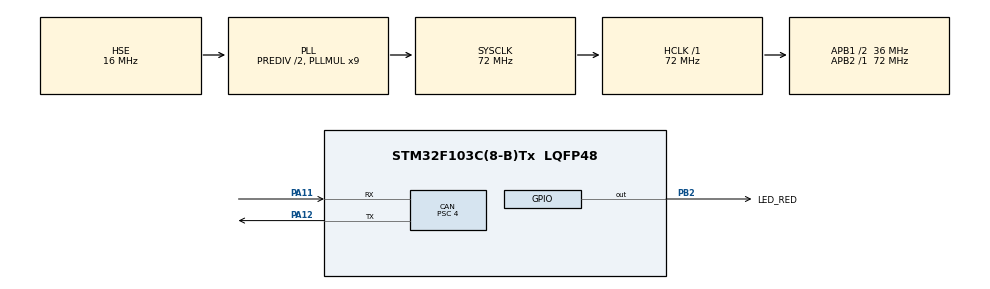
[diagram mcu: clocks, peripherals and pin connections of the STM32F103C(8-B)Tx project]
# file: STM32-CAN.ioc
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CAN.BS1=CAN_BS1_15TQ
CAN.BS2=CAN_BS2_2TQ
CAN.CalculateBaudRate=500000
CAN.CalculateTimeBit=2000
CAN.CalculateTimeQuantum=111.11111111111111
CAN.NART=ENABLE
CAN.Prescaler=4
CAN.SJW=CAN_SJW_2TQ
Mcu.Family=STM32F1
Mcu.Name=STM32F103C(8-B)Tx
Mcu.Package=LQFP48
NVIC.PriorityGroup=NVIC_PRIORITYGROUP_4
NVIC.USB_LP_CAN1_RX0_IRQn=true\:0\:0\:false\:false\:true\:true\:true\:true
PA11.Mode=CAN_Activate
PA11.Signal=CAN_RX
PA12.Mode=CAN_Activate
PA12.Signal=CAN_TX
PA13.GPIO_Label=J7_SWDIO
PA13.Mode=Serial_Wire
PA13.Signal=SYS_JTMS-SWDIO
PA14.GPIO_Label=J7_SWCLK
PA14.Mode=Serial_Wire
PA14.Signal=SYS_JTCK-SWCLK
PB2.GPIO_Label=LED_RED
PB2.Signal=GPIO_Output
PD0-OSC_IN.Mode=HSE-External-Oscillator
PD0-OSC_IN.Signal=RCC_OSC_IN
PD1-OSC_OUT.Mode=HSE-External-Oscillator
PD1-OSC_OUT.Signal=RCC_OSC_OUT
ProjectManager.HeapSize=0x200
ProjectManager.StackSize=0x400
ProjectManager.TargetToolchain=STM32CubeIDE
RCC.AHBFreq_Value=72000000
RCC.APB1CLKDivider=RCC_HCLK_DIV2
RCC.APB1Freq_Value=36000000
RCC.APB1TimFreq_Value=72000000
RCC.APB2Freq_Value=72000000
RCC.APB2TimFreq_Value=72000000
RCC.HCLKFreq_Value=72000000
RCC.HSEDivPLL=RCC_HSE_PREDIV_DIV2
RCC.HSE_VALUE=16000000
RCC.PLLMUL=RCC_PLL_MUL9
RCC.PLLSourceVirtual=RCC_PLLSOURCE_HSE
RCC.SYSCLKFreq_VALUE=72000000
RCC.SYSCLKSource=RCC_SYSCLKSOURCE_PLLCLK
RCC.USBFreq_Value=72000000
board=custom

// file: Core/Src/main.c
/* USER CODE BEGIN Header */
/**
 ******************************************************************************
 * @file           : main.c
 * @brief          : Main program body
 ******************************************************************************
 * @attention
 *
 * Copyright (c) 2024 STMicroelectronics.
 * All rights reserved.
 *
 * This software is licensed under terms that can be found in the LICENSE file
 * in the root directory of this software component.
 * If no LICENSE file comes with this software, it is provided AS-IS.
 *
 ******************************************************************************
 */
/* USER CODE END Header */
#include "main.h"

CAN_HandleTypeDef hcan;

/* USER CODE BEGIN PV */
// CAN Tx
CAN_TxHeaderTypeDef TxHeader;
uint8_t TxData[8];
uint32_t TxMailbox;

// CAN Rx
CAN_FilterTypeDef canfilterconfig;
CAN_RxHeaderTypeDef RxHeader;
uint8_t RxData[8];

/* USER CODE END PV */

void SystemClock_Config(void);
static void MX_GPIO_Init(void);
static void MX_CAN_Init(void);

/* USER CODE BEGIN 0 */

void setupTxCAN()
{
    TxHeader.StdId = 0x321;
    TxHeader.ExtId = 0x01;
    TxHeader.RTR = CAN_RTR_DATA;
    TxHeader.IDE = CAN_ID_EXT;
    TxHeader.DLC = 8;
    TxHeader.TransmitGlobalTime = DISABLE;

    TxData[0] = 0xA0;
    TxData[1] = 0xA1;
    TxData[2] = 0xA2;
    TxData[3] = 0xA3;
    TxData[4] = 0xA4;
    TxData[5] = 0xA5;
    TxData[6] = 0xA6;
    TxData[7] = 0xA7;
}

void setupRxCAN()
{
    canfilterconfig.FilterBank = 0;
    canfilterconfig.FilterMode = CAN_FILTERMODE_IDMASK;
    canfilterconfig.FilterScale = CAN_FILTERSCALE_32BIT;
    canfilterconfig.FilterIdHigh = 0x0000;
    canfilterconfig.FilterIdLow = 0x0356 << 3;  //read only 959. nothing else
    canfilterconfig.FilterMaskIdHigh = 0x0000;
    canfilterconfig.FilterMaskIdLow = 0xFFF8;
    canfilterconfig.FilterFIFOAssignment = CAN_RX_FIFO0;
    canfilterconfig.FilterActivation = ENABLE;
    canfilterconfig.SlaveStartFilterBank = 14;

    HAL_CAN_ConfigFilter(&hcan, &canfilterconfig);
    HAL_CAN_ActivateNotification(&hcan, CAN_IT_RX_FIFO0_MSG_PENDING); //enable interrupts
}

void txCAN()
{
    HAL_StatusTypeDef can_result = HAL_CAN_AddTxMessage(&hcan, &TxHeader,
            TxData, &TxMailbox);
    if (can_result != HAL_OK)
    {
        Error_Handler();
    }
}

/**
 * @brief  Rx Fifo 0 message pending callback in non blocking mode
 * @param  CanHandle: pointer to a CAN_HandleTypeDef structure that contains
 *         the configuration information for the specified CAN.
 * @retval None
 */
void HAL_CAN_RxFifo0MsgPendingCallback(CAN_HandleTypeDef *CanHandle)
{
    /* Get RX message */
    if (HAL_CAN_GetRxMessage(CanHandle, CAN_RX_FIFO0, &RxHeader, RxData)
            != HAL_OK)
    {
        /* Reception Error */
        Error_Handler();
    }

    HAL_GPIO_TogglePin(GPIOB, GPIO_PIN_2);
    // Echo received CAN message

    //RxData[7] = RxData[7] + 1;
    HAL_CAN_AddTxMessage(&hcan, &TxHeader, RxData, &TxMailbox);
}

uint32_t getUs(void)
{

    uint32_t usTicks = HAL_RCC_GetSysClockFreq() / 1000000;

    register uint32_t ms, cycle_cnt;
    do
    {
        ms = HAL_GetTick();
        cycle_cnt = SysTick->VAL;
    } while (ms != HAL_GetTick());
    return (ms * 1000) + (usTicks * 1000 - cycle_cnt) / usTicks;
}

void delayUs(uint16_t micros)
{
    uint32_t start = getUs();
    while (getUs() - start < (uint32_t) micros)
    {
        asm("nop");
    }
}

/* USER CODE END 0 */

int main(void)
{

  /* MCU Configuration--------------------------------------------------------*/

  /* Reset of all peripherals, Initializes the Flash interface and the Systick. */
  HAL_Init();

  /* Configure the system clock */
  SystemClock_Config();

  /* Initialize all configured peripherals */
  MX_GPIO_Init();
  MX_CAN_Init();
  /* USER CODE BEGIN 2 */
    setupTxCAN();
    setupRxCAN();
  /* USER CODE END 2 */

  /* Infinite loop */
  /* USER CODE BEGIN WHILE */
    while (1)
    {
        txCAN();
//        HAL_GPIO_TogglePin(GPIOB, GPIO_PIN_2);
        //delayUs(5000000);
        HAL_Delay(500);
    /* USER CODE END WHILE */

    }
}

void SystemClock_Config(void)
{
  RCC_OscInitTypeDef RCC_OscInitStruct = {0};
  RCC_ClkInitTypeDef RCC_ClkInitStruct = {0};

  /** Initializes the RCC Oscillators according to the specified parameters
  * in the RCC_OscInitTypeDef structure.
  */
  RCC_OscInitStruct.OscillatorType = RCC_OSCILLATORTYPE_HSE;
  RCC_OscInitStruct.HSEState = RCC_HSE_ON;
  RCC_OscInitStruct.HSEPredivValue = RCC_HSE_PREDIV_DIV2;
  RCC_OscInitStruct.HSIState = RCC_HSI_ON;
  RCC_OscInitStruct.PLL.PLLState = RCC_PLL_ON;
  RCC_OscInitStruct.PLL.PLLSource = RCC_PLLSOURCE_HSE;
  RCC_OscInitStruct.PLL.PLLMUL = RCC_PLL_MUL9;
  if (HAL_RCC_OscConfig(&RCC_OscInitStruct) != HAL_OK)
  {
    Error_Handler();
  }

  /** Initializes the CPU, AHB and APB buses clocks
  */
  RCC_ClkInitStruct.ClockType = RCC_CLOCKTYPE_HCLK|RCC_CLOCKTYPE_SYSCLK
                              |RCC_CLOCKTYPE_PCLK1|RCC_CLOCKTYPE_PCLK2;
  RCC_ClkInitStruct.SYSCLKSource = RCC_SYSCLKSOURCE_PLLCLK;
  RCC_ClkInitStruct.AHBCLKDivider = RCC_SYSCLK_DIV1;
  RCC_ClkInitStruct.APB1CLKDivider = RCC_HCLK_DIV2;
  RCC_ClkInitStruct.APB2CLKDivider = RCC_HCLK_DIV1;

  if (HAL_RCC_ClockConfig(&RCC_ClkInitStruct, FLASH_LATENCY_2) != HAL_OK)
  {
    Error_Handler();
  }
}

static void MX_CAN_Init(void)
{

  hcan.Instance = CAN1;
  hcan.Init.Prescaler = 4;
  hcan.Init.Mode = CAN_MODE_NORMAL;
  hcan.Init.SyncJumpWidth = CAN_SJW_2TQ;
  hcan.Init.TimeSeg1 = CAN_BS1_15TQ;
  hcan.Init.TimeSeg2 = CAN_BS2_2TQ;
  hcan.Init.TimeTriggeredMode = DISABLE;
  hcan.Init.AutoBusOff = DISABLE;
  hcan.Init.AutoWakeUp = DISABLE;
  hcan.Init.AutoRetransmission = ENABLE;
  hcan.Init.ReceiveFifoLocked = DISABLE;
  hcan.Init.TransmitFifoPriority = DISABLE;
  if (HAL_CAN_Init(&hcan) != HAL_OK)
  {
    Error_Handler();
  }
  /* USER CODE BEGIN CAN_Init 2 */

    if (HAL_CAN_Start(&hcan) != HAL_OK)
    {
        /* Start Error */
        Error_Handler();
    }

  /* USER CODE END CAN_Init 2 */

}

static void MX_GPIO_Init(void)
{
  GPIO_InitTypeDef GPIO_InitStruct = {0};

  /* GPIO Ports Clock Enable */
  __HAL_RCC_GPIOD_CLK_ENABLE();
  __HAL_RCC_GPIOB_CLK_ENABLE();
  __HAL_RCC_GPIOA_CLK_ENABLE();

  /*Configure GPIO pin Output Level */
  HAL_GPIO_WritePin(LED_RED_GPIO_Port, LED_RED_Pin, GPIO_PIN_RESET);

  /*Configure GPIO pin : LED_RED_Pin */
  GPIO_InitStruct.Pin = LED_RED_Pin;
  GPIO_InitStruct.Mode = GPIO_MODE_OUTPUT_PP;
  GPIO_InitStruct.Pull = GPIO_NOPULL;
  GPIO_InitStruct.Speed = GPIO_SPEED_FREQ_LOW;
  HAL_GPIO_Init(LED_RED_GPIO_Port, &GPIO_InitStruct);

}

void Error_Handler(void)
{
  /* USER CODE BEGIN Error_Handler_Debug */
    /* User can add his own implementation to report the HAL error return state */
    __disable_irq();
    uint32_t CAN_ERR = HAL_CAN_GetError(&hcan);
    while (1)
    {

    }
  /* USER CODE END Error_Handler_Debug */
}
